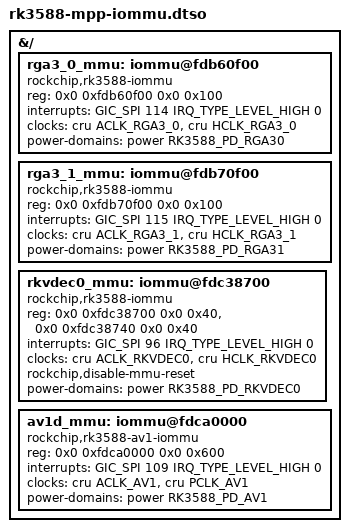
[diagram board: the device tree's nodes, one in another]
// SPDX-License-Identifier: (GPL-2.0+ OR MIT)
/*
 * The IOMMUs rk3588-mpp.dtso uses that mainline device trees only have since
 * Linux 7.x. The module applies this only when the device tree lacks them: the
 * mainline IOMMU driver binds the mainline nodes at boot, and a second node for
 * the same registers can't probe. Built with -@, so the labels land in
 * /__symbols__.
 */

/dts-v1/;
/plugin/;

#include <dt-bindings/clock/rockchip,rk3588-cru.h>
#include <dt-bindings/interrupt-controller/arm-gic.h>
#include <dt-bindings/interrupt-controller/irq.h>
#include <dt-bindings/power/rk3588-power.h>

&{/} {
	rga3_0_mmu: iommu@fdb60f00 {
		compatible = "rockchip,rk3588-iommu", "rockchip,rk3568-iommu";
		reg = <0x0 0xfdb60f00 0x0 0x100>;
		interrupts = <GIC_SPI 114 IRQ_TYPE_LEVEL_HIGH 0>;
		clocks = <&cru ACLK_RGA3_0>, <&cru HCLK_RGA3_0>;
		clock-names = "aclk", "iface";
		power-domains = <&power RK3588_PD_RGA30>;
		#iommu-cells = <0>;
	};

	rga3_1_mmu: iommu@fdb70f00 {
		compatible = "rockchip,rk3588-iommu", "rockchip,rk3568-iommu";
		reg = <0x0 0xfdb70f00 0x0 0x100>;
		interrupts = <GIC_SPI 115 IRQ_TYPE_LEVEL_HIGH 0>;
		clocks = <&cru ACLK_RGA3_1>, <&cru HCLK_RGA3_1>;
		clock-names = "aclk", "iface";
		power-domains = <&power RK3588_PD_RGA31>;
		#iommu-cells = <0>;
	};

	rkvdec0_mmu: iommu@fdc38700 {
		compatible = "rockchip,rk3588-iommu", "rockchip,rk3568-iommu";
		reg = <0x0 0xfdc38700 0x0 0x40>, <0x0 0xfdc38740 0x0 0x40>;
		interrupts = <GIC_SPI 96 IRQ_TYPE_LEVEL_HIGH 0>;
		clocks = <&cru ACLK_RKVDEC0>, <&cru HCLK_RKVDEC0>;
		clock-names = "aclk", "iface";
		rockchip,disable-mmu-reset;
		#iommu-cells = <0>;
		power-domains = <&power RK3588_PD_RKVDEC0>;
	};

	/* as mainline (Linux 7.x) describes it, for vsi-iommu */
	av1d_mmu: iommu@fdca0000 {
		compatible = "rockchip,rk3588-av1-iommu", "verisilicon,iommu-1.2";
		reg = <0x0 0xfdca0000 0x0 0x600>;
		interrupts = <GIC_SPI 109 IRQ_TYPE_LEVEL_HIGH 0>;
		clocks = <&cru ACLK_AV1>, <&cru PCLK_AV1>;
		clock-names = "core", "iface";
		#iommu-cells = <0>;
		power-domains = <&power RK3588_PD_AV1>;
	};
};
